# DP32G030 register map
File version: 1.0
CPU: CM0 r0p0, little endian, 4 interrupt priority bits
Registers are 32-bit, access not given, reset 0x0 unless marked. A register's access mark holds for its fields unless they carry their own. Offsets are from the block's base; [hi:lo] are bit positions; {n}, {i} and the like mark numbered series.

## IWDT — IWDT unit
Base 0x4006A000
0x00 IWDT_LOAD reset 0xFFFF — IWDT initial value register
0x08 IWDT_CTRL — IWDT control register
0x0C IWDT_IF — IWDT status register
0x10 IWDT_FEED — IWDT feeding dog register

## WWDT — WWDT unit
Base 0x4006A800
0x00 WWDT_LOAD reset 0x40 — WWDT initial value register
0x04 WWDT_VALUE reset 0x7F — WWDT Current count value register
0x08 WWDT_CTRL — WWDT control register
0x0C WWDT_IF — WWDT Interrupt Status Register
0x10 WWDT_FEED — WWDT feeding dog register

## UART0 — UART0 unit
Base 0x4006B000
0x00 UART0_CTRL — UART control register
0x04 UART0_BAUD — UART Baud Rate Configuration Register
0x08 UART0_TDR — UART write data register
0x0C UART0_RDR — UART read data register
0x10 UART0_IE — UART interrupt enable register
0x14 UART0_IF reset 0x2400 — UART Interrupt Status Register
0x18 UART0_FIFO reset 0x7 — UART FIFO control register
0x1C UART0_FC — UART Flow Control Configuration Register
0x20 UART0_RXTO reset 0xFF — UART Receive Timeout Configuration Register

## UART1 — UART1 unit
Base 0x4006B800
Registers as UART0 (with UART0 read as UART1).

## UART2 — UART2 unit
Base 0x4006C000
Registers as UART0 (with UART0 read as UART2).

## FLASH_CTRL — FLASH_CTRL unit
Base 0x4006F000
0x00 FLASH_CFG reset 0x80000000 — Flash configuration register
0x04 FLASH_ADDR — Flash Address Configuration Register
0x08 FLASH_WDATA — Flash write data register
0x0C FLASH_RDATA — Flash read data register
0x10 FLASH_START — Flash Operation Start Register
0x14 FLASH_STATUS reset 0x5
0x18 FLASH_LOCK — Flash Operation Lock Control Register
0x1C FLASH_UNLOCK — Flash Operation Unlock Control Register
0x20 FLASH_MASK reset 0x2 — Flash mask control register
0x24 FLASH_ERASETIME reset 0x7532A31B — Flash Erase Time Parameter Configuration Register
0x28 FLASH_PROGTIME reset 0x1F4360 — Flash Program Time Parameter Configuration Register

## PORTCON — PORTCON unit
Base 0x400B0000
0x00 PORTA_SEL0 — PORTA Function Select Register0
0x04 PORTA_SEL1 — PORTA Function Select Register1
0x08 PORTB_SEL0 reset 0xFFFF0000 — PORTB Function Select Register0
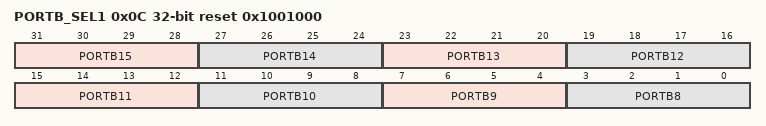
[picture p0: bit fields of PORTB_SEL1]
0x0C PORTB_SEL1 rw reset 0x1001000 — PORTB Function Select Register1
  [31:28] PORTB15 — FUNCTION
  [27:24] PORTB14 — 0001:SWCLK
  [23:20] PORTB13 — FUNCTION
  [19:16] PORTB12 — FUNCTION
  [15:12] PORTB11 — 0001:SWDIO
  [11:8] PORTB10 — FUNCTION
  [7:4] PORTB9 — FUNCTION
  [3:0] PORTB8 — FUNCTION
0x10 PORTC_SEL0 — PORTC Function Select Register0
0x100 PORTA_IE — PORTA Input enable register
0x104 PORTB_IE reset 0x4800 — PORTB Input enable register
0x108 PORTC_IE reset 0x20 — PORTC Input enable register
0x200 PORTA_PU — PORTA pull-up enable register
0x204 PORTB_PU — PORTB pull-up enable register
0x208 PORTC_PU — PORTC pull-up enable register
0x300 PORTA_PD — PORTA pull-down enable register
0x304 PORTB_PD — PORTB pull-down enable register
0x308 PORTC_PD reset 0x20 — PORTC pull-down enable register
0x400 PORTA_OD — PORTA Open Drain Enable Register
0x404 PORTB_OD — PORTB Open Drain Enable Register
0x408 PORTC_OD — PORTC Open Drain Enable Register
0x500 PORTA_WKE — PORTA wakeup enable register
0x504 PORTB_WKE — PORTB wakeup enable register
0x508 PORTC_WKE — PORTC wakeup enable register
0x600 PORT_CFG reset 0x15 — port configuration register
0x700 PORTA_WK_SEL — PORTA wakeIOedge selection register
0x704 PORTB_WK_SEL — PORTB wakeIOedge selection register
0x708 PORTC_WK_SEL — PORTC wakeIOedge selection register

## PWM_BASE0 — PWM_BASE0 unit
Base 0x400B1000
0x00 PWMBASE0_EN — PWMBASE enable register
0x04 PWMBASE0_DIV — PWMBASE Clock Prescaler Register
0x08 PWMBASE0_CON — PWMBASE Output Configuration Register
0x0C PWMBASE0_PERIOD — PWMBASE Period configuration register
0x10 PWMBASE0_IE — PWMBASE interrupt enable register
0x14 PWMBASE0_IF — PWMBASE Interrupt Status Register
0x18 PWMBASE0_CNT reset 0xFFFF — PWMBASE Current count value register
0x20 PWMBASE0_CH0_COMP — PWMBASE0 Toggle Point Configuration Register
0x30 PWMBASE0_CH1_COMP — PWMBASE1 Toggle Point Configuration Register
0x40 PWMBASE0_CH2_COMP — PWMBASE2 Toggle Point Configuration

## PWM_BASE1 — PWM_BASE1 unit
Base 0x400B1800
0x00 PWMBASE1_EN — PWMBASE enable register
0x04 PWMBASE1_DIV — PWMBASE Clock Prescaler Register
0x08 PWMBASE1_CON — PWMBASE Output Configuration Register
0x0C PWMBASE1_PERIOD — PWMBASE Period configuration register
0x10 PWMBASE1_IE — PWMBASE interrupt enable register
0x14 PWMBASE1_IF — PWMBASE Interrupt Status Register
0x18 PWMBASE1_CNT reset 0xFFFF — PWMBASE Current count value register
0x20 PWMBASE1_CH0_COMP — PWMBASE0 Toggle Point Configuration Register
0x30 PWMBASE1_CH1_COMP — PWMBASE1 Toggle Point Configuration Register
0x40 PWMBASE1_CH2_COMP — PWMBASE2 Toggle Point Configuration

## PWM_PLUS0 — PWM_PLUS0 unit
Base 0x400B4000
0x00 PPWMPLUS0_CFG — PWMPLUS0_CFG
0x04 PWMPLUS0_GEN
0x08 PWMPLUS0_CLKSRC
0x0C PWMPLUS0_BRAKE_CFG
0x10 PWMPLUS0_MASK_LEV
0x1C PWMPLUS0_PERIOD reset 0xFFFF
{0x20+4i} PWMPLUS0_CH{i}_COMP (i=0..2)
{0x30+4i} PWMPLUS0_CH{i}_DT (i=0..2)
0x40 PWMPLUS0_TRIG_COMP
0x44 PWMPLUS0_TRIG_CFG
0x60 PWMPLUS0_IE
0x64 PWMPLUS0_IF
0x84 PWMPLUS0_SWLOAD
0x88 PWMPLUS0_MASK_EN
0xE0 PWMPLUS0_CNT_ST
0xE4 PWMPLUS0_BRAKE_ST

## PWM_PLUS1 — PWM_PLUS1 unit
Base 0x400B4800
0x00 PWMPLUS1_CFG
0x04 PWMPLUS1_GEN
0x08 PWMPLUS1_CLKSRC
0x0C PWMPLUS1_BRAKE_CFG
0x10 PWMPLUS1_MASK_LEV
0x1C PWMPLUS1_PERIOD reset 0xFFFF
{0x20+4i} PWMPLUS1_CH{i}_COMP (i=0..2)
{0x30+4i} PWMPLUS1_CH{i}_DT (i=0..2)
0x40 PWMPLUS1_TRIG_COMP
0x44 PWMPLUS1_TRIG_CFG
0x60 PWMPLUS1_IE
0x64 PWMPLUS1_IF
0x84 PWMPLUS1_SWLOAD
0x88 PWMPLUS1_MASK_EN
0xE0 PWMPLUS1_CNT_ST
0xE4 PWMPLUS1_BRAKE_ST

## SPI0 — SPI0 unit
Base 0x400B8000
0x00 SPI0_CR reset 0x1010 — SPIcontrol register
0x04 SPI0_WDR — SPI write data register
0x08 SPI0_RDR — SPI read data register
0x10 SPI0_IE — SPI interrupt enable register
0x14 SPI0_IF reset 0x8 — SPI Interrupt Status Register
0x18 SPI0_FIFOST reset 0x9 — SPI FIFO status register

## SPI1 — SPI1 unit
Base 0x400B8800
Registers as SPI0 (with SPI0 read as SPI1).

## IIC0 — IIC0 unit
Base 0x400B9000
0x00 IIC0_CCFG reset 0x18 — General Configuration Register
0x04 IIC0_CST reset 0x6 — General Status Register
0x08 IIC0_CTRANS reset 0x2 — general transfer register
0x0C IIC0_RXDATA — Receive Data Register
0x10 IIC0_TXDATA — send data register
0x14 IIC0_IE — interrupt enable register
0x18 IIC0_IF reset 0x1 — Interrupt Flag Register
0x20 IIC0_MCTRL — Host Mode Control Register
0x24 IIC0_MSPC reset 0x33F7F — Timing Configuration Register
0x30 IIC0_SCTRL reset 0x8 — Slave Mode Control Register
0x34 IIC0_SADDR — Slave Mode Address Register

## IIC1 — IIC1 unit
Base 0x400B9800
Registers as IIC0 (with IIC0 read as IIC1).

## SARADC — SARADC unit
Base 0x400BA000
0x00 ADC_CFG — ADC configuration register
0x04 ADC_START — ADC boot register
0x08 ADC_IE — ADC interrupt enable register
0x0C ADC_IF — ADC Interrupt status Register
{0x10+8i} ADC_CH{i}_STAT (i=0..15) — ADC{i} status register
{0x14+8i} ADC_CH{i}_DATA (i=0..15) — ADC{i} data register
0xA0 ADC_FIFO_STAT reset 0x4 — ADC FIFO status register
0xA4 ADC_FIFO_DATA
0xB0 EXTTRIG_SEL — External signal trigger ADC
0xF0 ADC_CALIB_OFFSET — ADC calibration OFFSET register
0xF4 ADC_CALIB_KD — ADC calibration KD register

## AES128 — AES128 unit
Base 0x400BD000
0x00 AES_CR — AES control register
0x04 AES_SR — AES status register
0x08 AES_DINR — AES input data register
0x0C AES_DOUTR — AES output data register
{0x10+4i} AES_KEYR{i} (i=0..3) — AES key register{i}
{0x20+4i} AES_IVR{i} (i=0..3) — AES Encryption starting point register{i}
